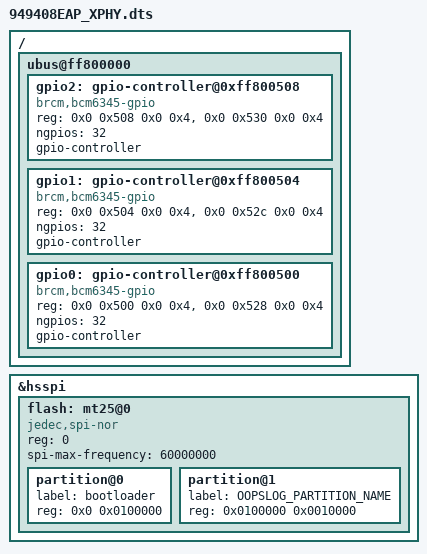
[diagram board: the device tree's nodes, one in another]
#include "94908.dts"

/ {
	ubus@ff800000 {
		/* actual count 84 GPIOs */
		gpio2: gpio-controller@0xff800508 {
			compatible = "brcm,bcm6345-gpio";
			reg-names = "dirout", "dat";
			reg = <0x0 0x508 0x0 0x4>, <0x0 0x530 0x0 0x4>;
			ngpios = <32>;

			#gpio-cells = <2>;
			gpio-controller;
		};
		gpio1: gpio-controller@0xff800504 {
			compatible = "brcm,bcm6345-gpio";
			reg-names = "dirout", "dat";
			reg = <0x0 0x504 0x0 0x4>, <0x0 0x52c 0x0 0x4>;
			ngpios = <32>;

			#gpio-cells = <2>;
			gpio-controller;
		};
		gpio0: gpio-controller@0xff800500 {
			compatible = "brcm,bcm6345-gpio";
			reg-names = "dirout", "dat";
			reg = <0x0 0x500 0x0 0x4>, <0x0 0x528 0x0 0x4>;
			ngpios = <32>;

			#gpio-cells = <2>;
			gpio-controller;
		};
	};
};

&hsspi { 
      flash: mt25@0 {
      status = "okay";
      compatible = "jedec,spi-nor";
      reg = <0>; /* chip select 0 */
      spi-max-frequency = <60000000>;
      #address-cells = <1>;
      #size-cells = <1>;
      partition@0 {
           label = "bootloader";
           reg = <0x0 0x0100000>;
           };
      partition@1 {
           label = OOPSLOG_PARTITION_NAME;
           reg = <0x0100000 0x0010000>;
           };
       };
};
